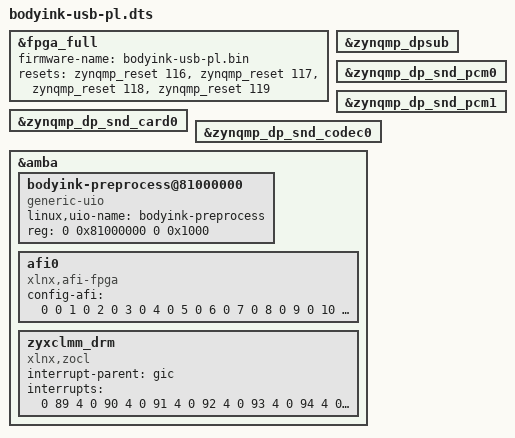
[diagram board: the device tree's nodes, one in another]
/dts-v1/;
/plugin/;

/ {
    fragment@0 {
        target = <&fpga_full>;
        __overlay__ {
            #address-cells = <2>;
            #size-cells = <2>;
            firmware-name = "bodyink-usb-pl.bin";
            resets = <&zynqmp_reset 116>, <&zynqmp_reset 117>,
                     <&zynqmp_reset 118>, <&zynqmp_reset 119>;
        };
    };
    fragment@1 {target = <&zynqmp_dpsub>; __overlay__ {status = "okay";};};
    fragment@2 {target = <&zynqmp_dp_snd_pcm0>; __overlay__ {status = "okay";};};
    fragment@3 {target = <&zynqmp_dp_snd_pcm1>; __overlay__ {status = "okay";};};
    fragment@4 {target = <&zynqmp_dp_snd_card0>; __overlay__ {status = "okay";};};
    fragment@5 {target = <&zynqmp_dp_snd_codec0>; __overlay__ {status = "okay";};};
    fragment@6 {
        target = <&amba>;
        __overlay__ {
            #address-cells = <2>;
            #size-cells = <2>;
            bodyink-preprocess@81000000 {
                compatible = "generic-uio";
                linux,uio-name = "bodyink-preprocess";
                reg = <0 0x81000000 0 0x1000>;
                status = "okay";
                /* Polling only: the PL interrupt enable remains zero. */
            };
            afi0 {
                compatible = "xlnx,afi-fpga";
                config-afi = <0 0 1 0 2 0 3 0 4 0 5 0 6 0 7 0
                              8 0 9 0 10 0 11 0 12 0 13 0 14 0 15 0>;
            };
            zyxclmm_drm {
                compatible = "xlnx,zocl";
                status = "okay";
                interrupt-parent = <&gic>;
                interrupts = <0 89 4 0 90 4 0 91 4 0 92 4
                              0 93 4 0 94 4 0 95 4 0 96 4>;
            };
        };
    };
};
